# VPAC0_DRU_UTC_VPAC0_DRU_MMR_CFG_DRU_DRU_CHRT register map
Vendor: Texas Instruments
Peripheral module from a debugger description file (folder J721S2).
Registers are 64-bit, read-write, reset 0x0 unless marked. A register's access mark holds for its fields unless they carry their own. Offsets are as the file gives them; lines under a group give offsets from that group; [hi:lo] are bit positions; {n}, {i} and the like mark numbered series; 'fields as' and 'values as' point back to an identical list; <NAME> marks a mode.

## VPAC0_DRU_UTC_VPAC0_DRU_MMR_CFG_DRU_DRU_CHRT
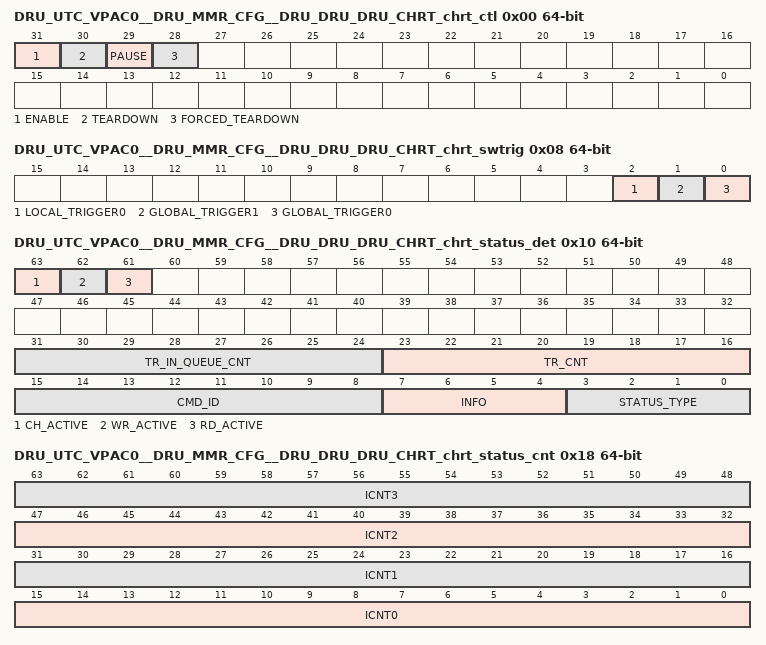
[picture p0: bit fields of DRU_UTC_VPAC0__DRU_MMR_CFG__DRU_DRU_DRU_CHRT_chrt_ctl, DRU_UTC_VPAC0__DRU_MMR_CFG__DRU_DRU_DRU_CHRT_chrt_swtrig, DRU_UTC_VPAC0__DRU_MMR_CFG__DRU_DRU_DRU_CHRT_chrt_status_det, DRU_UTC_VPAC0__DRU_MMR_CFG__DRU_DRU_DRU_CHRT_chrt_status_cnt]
0x00 DRU_UTC_VPAC0__DRU_MMR_CFG__DRU_DRU_DRU_CHRT_chrt_ctl — The channel realtime control register contains real-time cotrol and status information for the DMA Channel. The fields in this regsiter can be changed while the channel is in operation.
  [31] ENABLE — This field enables or disables the channel. Disabling a channel halts operation on the channel after the current block transfer is completed. Disabling a channel in the middle of a packet transfer may result in underflow conditions in the attached application block and data loss. This field is encoded as follows: 0 = channel is disabled 1 = channel is enabled This field will be cleared after a channel teardown is complete.
  [30] TEARDOWN — Channel teardown: Setting this bit will request the channel to be torn down. This field will remain set after a channel teardown is complete.
  [29] PAUSE — Channel pause: Setting this bit will request the channel to pause processing at the next packet boundary. This is a more graceful method of halting processing than disabling the channel as it will not allow any current packets to underflow.
  [28] FORCED_TEARDOWN — Channel forced teardown: Setting this bit will request the channel to be torn down forcefulyy. This field will clear after a channel teardown is complete.
0x08 DRU_UTC_VPAC0__DRU_MMR_CFG__DRU_DRU_DRU_CHRT_chrt_swtrig — The Software Trigger Register provides a mechanism by which software can directly trigger the channel in a secure way.
  [2] LOCAL_TRIGGER0 — Trigger: writing this bit with a value of 1 will cause the trigger event to be sent to this channel. This will trigger LOCAL Event
  [1] GLOBAL_TRIGGER1 — Trigger: writing this bit with a value of 1 will cause the trigger event to be sent to this channel. This will trigger Global Event 1
  [0] GLOBAL_TRIGGER0 — Trigger: writing this bit with a value of 1 will cause the trigger event to be sent to this channel. This will trigger Global Event 0
0x10 DRU_UTC_VPAC0__DRU_MMR_CFG__DRU_DRU_DRU_CHRT_chrt_status_det ro — The channel status details
  [63] CH_ACTIVE — The channel has some active work
  [62] WR_ACTIVE — The top TR has submitted a sub-TR to the write portion of the queue
  [61] RD_ACTIVE — The top TR has submitted a sub-TR to the read portion of the queue
  [31:24] TR_IN_QUEUE_CNT — The number of TRs for the channel that are in the queue FIFO
  [23:16] TR_CNT — The number of TRs in the channel FIFO
  [15:8] CMD_ID — The last cmd_id given to the write queue
  [7:4] INFO — The info of the error that was received
  [3:0] STATUS_TYPE — The type of error that was received
0x18 DRU_UTC_VPAC0__DRU_MMR_CFG__DRU_DRU_DRU_CHRT_chrt_status_cnt ro — The channel count details
  [16n+15:16n] ICNT{n} (n=0..3) — The last icnt{n} given to the write queue
